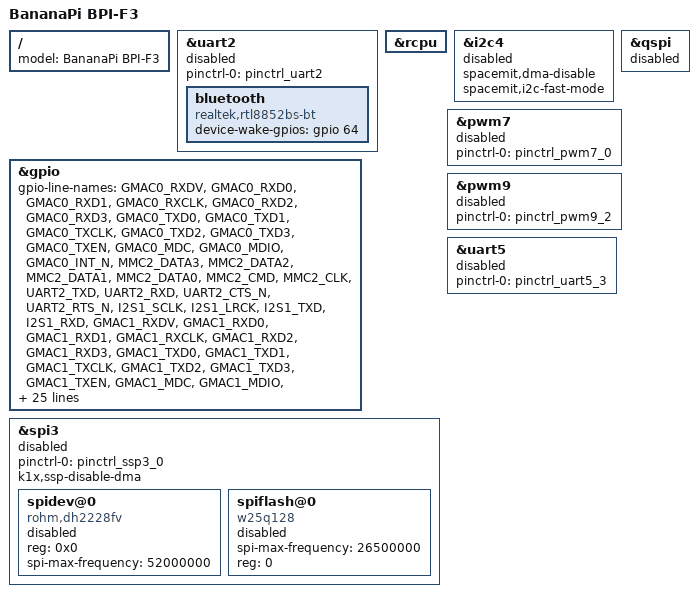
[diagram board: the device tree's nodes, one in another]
// SPDX-License-Identifier: (GPL-2.0 OR MIT)
/* Copyright (c) 2024 Spacemit, Inc */

/dts-v1/;

#include "k1-x_deb1.dts"

/ {
	model = "BananaPi BPI-F3";
};

&uart2 {
	pinctrl-names = "default";
	pinctrl-0 = <&pinctrl_uart2>;
	status = "disabled";

	bluetooth {
		compatible = "realtek,rtl8852bs-bt";
		device-wake-gpios = <&gpio 64 GPIO_ACTIVE_HIGH>;
	};
};

&gpio {
	gpio-line-names =
		"GMAC0_RXDV",
		"GMAC0_RXD0",
		"GMAC0_RXD1",
		"GMAC0_RXCLK",
		"GMAC0_RXD2",
		"GMAC0_RXD3",
		"GMAC0_TXD0",
		"GMAC0_TXD1",
		"GMAC0_TXCLK",
		"GMAC0_TXD2",
		"GMAC0_TXD3",
		"GMAC0_TXEN",
		"GMAC0_MDC",
		"GMAC0_MDIO",
		"GMAC0_INT_N",
		"MMC2_DATA3",
		"MMC2_DATA2",
		"MMC2_DATA1",
		"MMC2_DATA0",
		"MMC2_CMD",
		"MMC2_CLK",
		"UART2_TXD",
		"UART2_RXD",
		"UART2_CTS_N",
		"UART2_RTS_N",
		"I2S1_SCLK",
		"I2S1_LRCK",
		"I2S1_TXD",
		"I2S1_RXD",
		"GMAC1_RXDV",
		"GMAC1_RXD0",
		"GMAC1_RXD1",
		"GMAC1_RXCLK",
		"GMAC1_RXD2",
		"GMAC1_RXD3",
		"GMAC1_TXD0",
		"GMAC1_TXD1",
		"GMAC1_TXCLK",
		"GMAC1_TXD2",
		"GMAC1_TXD3",
		"GMAC1_TXEN",
		"GMAC1_MDC",
		"GMAC1_MDIO",
		"GMAC1_INT_N",
		"LCD_BL_PWM_1V8",
		"GMAC0_CLK_REF",
		"GMAC1_CLK_REF",
		"CON_P08",
		"CON_P10",
		"CON_P22",
		"CON_P26",
		"CON_P05",
		"CON_P03",
		"CAM_MCLK0",
		"CAM_I2C0_SCL",
		"CAM_I2C0_SDA",
		"TP_I2C1_SCL",
		"TP_I2C1_SDA",
		"TP_INT_1V8",
		"PCIEB_PERSTN",
		"PCIEB_WAKEN",
		"PCIEB_CLKREQN",
		"PCIEC_PERSTN",
		"BT_RESETN",
		"AP_WAKE_BT",
		"BT_WAKE_AP",
		"WL_WAKE_AP",
		"WL_REG_ON",
		"DEBUG_UART0_TXD",
		"DEBUG_UART0_RXD",
		"CON_P07",
		"CON_P11",
		"CON_P13",
		"CON_P15",
		"CON_P12",
		"CON_P23",
		"CON_P24",
		"CON_P19",
		"CON_P21",
		"FAN_PWM",
		"SD_CD_3V3",
		"LCD_RST_1V8",
		"LCD_BL_EN_1V8",
		"LCD_PWR_EN_1V8",
		"EEPROM_I2C2_SCL",
		"EEPROM_I2C2_SDA",
		"HDMI_SCL",
		"HDMI_SDA",
		"HDMI_CEC",
		"HDMI_HPD",
		"WL_POWER",
		"CON_P16",
		"CON_P18",
		"PWR_SCL",
		"PWR_SDA",
		"SLEEP_OUT",
		"LED-G",
		"USB3_PWREN",
		"QSPI_DATA3",
		"QSPI_DATA2",
		"QSPI_DATA1",
		"QSPI_DATA0",
		"QSPI_CLK",
		"QSPI_CS1",
		"MMC1_DATA3",
		"MMC1_DATA2",
		"MMC1_DATA1",
		"MMC1_DATA0",
		"MMC1_CMD",
		"MMC1_CLK",
		"GMAC0_RSTn_L",
		"CAMERA0_RST",
		"PCIEC_WAKEN",
		"CAMERA0_PDN",
		"TP_RST_1V8",
		"GMAC1_RSTn_L",
		"WL_DIS_N",
		"PCIEC_CLKREQN",
		"I2S0_SCLK",
		"I2S0_LRCK",
		"I2S0_OUT",
		"I2S0_IN",
		"I2S0_SYSCLK",
		"USB3_HUB_PWREN",
		"USB3_HUB_RST",
		"USB2_VBUS_ON0",
		"CODEC_IRQ",
		"PA_SHUTDOWN";
};

&rcpu {
	/delete-property/ pinctrl-names;
	/delete-property/ pinctrl-0;
};

&i2c4 {
	spacemit,dma-disable;
	//spacemit,i2c-high-mode;
	spacemit,i2c-fast-mode;
	status = "disabled";
};

&qspi {
        status = "disabled";
};

&spi3 {
	pinctrl-names = "default";
	pinctrl-0 = <&pinctrl_ssp3_0>;
	k1x,ssp-disable-dma;
	status = "disabled";

	spidev@0 {
		compatible = "rohm,dh2228fv";
		reg = <0x0>;
		spi-max-frequency = <52000000>;
		status = "disabled";
	};

	spiflash@0 {
		compatible = "w25q128", "jedec,spi-nor", "winbond,w25q128";
		spi-max-frequency = <26500000>;
		reg = <0>;
		status = "disabled";
	};
};

&pwm7 {
	pinctrl-names = "default";
	pinctrl-0 = <&pinctrl_pwm7_0>;
	status = "disabled";
};

&pwm9 {
	pinctrl-names = "default";
	pinctrl-0 = <&pinctrl_pwm9_2>;
	status = "disabled";
};

&uart5 {
	pinctrl-names = "default";
	pinctrl-0 = <&pinctrl_uart5_3>;
	status = "disabled";
};
